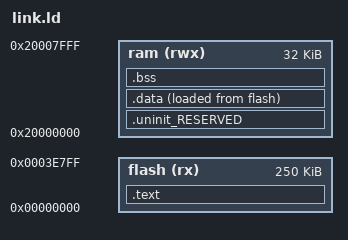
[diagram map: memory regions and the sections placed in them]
MEMORY
{
  flash (rx) : ORIGIN = 0x00000000, LENGTH = 0x3e800
  ram  (rwx) : ORIGIN = 0x20000000, LENGTH = 32K
}

ENTRY(irq_handler_reset)

SECTIONS
{
  .text : ALIGN(4)
  {
    FILL(0xff)
    KEEP(*(.vectors))
    *(.text*)
    *(.rodata)
    *(.rodata.*)
    . = ALIGN(4);
  } > flash

  . = ALIGN(4);
  _etext = .;

  .uninit_RESERVED : ALIGN(4)
  {
    KEEP(*(.bss.$RESERVED*))
  } > ram

  .data : ALIGN(4)
  {
    FILL(0xff)
    _data = .;
    *(.ramfunc .ramfunc.*);
    *(vtable)
    *(.data*)
    . = ALIGN(4);
    _edata = .;
  } > ram AT > flash

  .bss : ALIGN(4)
  {
    _bss = .;
    *(.bss*)
    *(COMMON)
    . = ALIGN(4);
    _ebss = .;
    PROVIDE(_end = .);
  } > ram
}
